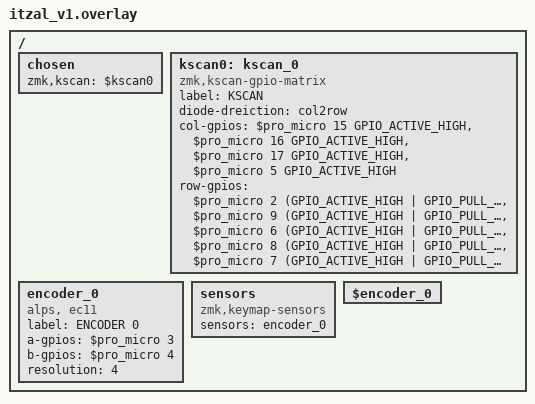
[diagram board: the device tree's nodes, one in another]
/*
 * Copyright (c) 2020 The ZMK Contributors
 *
 * SPDX-License-Identifier: MIT
 */

/ {
	chosen {
		zmk,kscan = $kscan0;
	};

	kscan0: kscan_0 {
		compatible = "zmk,kscan-gpio-matrix";
		label = "KSCAN";
		diode-dreiction = "col2row";

		col-gpios
			= <$pro_micro 15 GPIO_ACTIVE_HIGH>
			, <$pro_micro 16 GPIO_ACTIVE_HIGH>
			, <$pro_micro 17 GPIO_ACTIVE_HIGH>
			, <$pro_micro 5 GPIO_ACTIVE_HIGH>
			;

		row-gpios
			= <$pro_micro 2 (GPIO_ACTIVE_HIGH | GPIO_PULL_DOWN)>
			, <$pro_micro 9 (GPIO_ACTIVE_HIGH | GPIO_PULL_DOWN)>
			, <$pro_micro 6 (GPIO_ACTIVE_HIGH | GPIO_PULL_DOWN)>
			, <$pro_micro 8 (GPIO_ACTIVE_HIGH | GPIO_PULL_DOWN)>
			, <$pro_micro 7 (GPIO_ACTIVE_HIGH | GPIO_PULL_DOWN)>
			;
	};

	encoder_0: encoder_0 {
		compatible = "alps, ec11";
		label = "ENCODER 0";
		a-gpios = <$pro_micro 3 (GPIO_ACTIVE_HIGH | GPIO_PULL_UP);
		b-gpios = <$pro_micro 4 (GPIO_ACTIVE_HIGH | GPIO_PULL_UP);
		resolution = <4>;
	};

	sensors {
		compatible = "zmk,keymap-sensors";
		sensors = <&encoder_0>;
	};

	$encoder_0 {
		status = "okay";
	};
};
